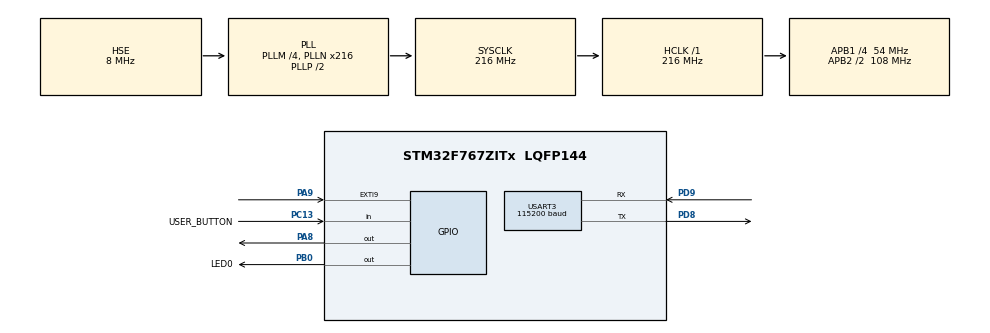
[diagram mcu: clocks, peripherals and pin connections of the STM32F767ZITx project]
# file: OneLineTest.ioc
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Mcu.Family=STM32F7
NVIC.USART3_IRQn=true\:2\:0\:true\:false\:true\:true\:true
RCC.PLLSourceVirtual=RCC_PLLSOURCE_HSE
RCC.CortexFreq_Value=216000000
PC13.Signal=GPIO_Input
PC14/OSC32_IN.Mode=LSE-External-Oscillator
PB0.GPIO_Label=LED0
PD9.Signal=USART3_RX
PC13.GPIO_Label=USER_BUTTON
RCC.APB1CLKDivider=RCC_HCLK_DIV4
PD9.Mode=Asynchronous
RCC.SYSCLKSource=RCC_SYSCLKSOURCE_PLLCLK
ProjectManager.StackSize=0x1000
USART3.VirtualMode-Asynchronous=VM_ASYNC
PA13.Signal=SYS_JTMS-SWDIO
USART3.BaudRate=115200
ProjectManager.TargetToolchain=MDK-ARM V5.27
PH0/OSC_IN.Mode=HSE-External-Clock-Source
RCC.HCLKFreq_Value=216000000
RCC.APB2TimFreq_Value=216000000
PA9.Signal=GPXTI9
PH1/OSC_OUT.Signal=RCC_OSC_OUT
PD8.Signal=USART3_TX
RCC.USBFreq_Value=216000000
TIM4.Prescaler=53
PD8.Mode=Asynchronous
RCC.AHBFreq_Value=216000000
RCC.HSE_VALUE=8000000
board=custom
RCC.VCOOutputFreq_Value=432000000
PH0/OSC_IN.Signal=RCC_OSC_IN
RCC.APB2Freq_Value=108000000
PA14.Mode=Serial_Wire
PA8.Signal=GPIO_Output
TIM4.Period=249
PA13.Mode=Serial_Wire
PH1/OSC_OUT.Mode=HSE-External-Clock-Source
Mcu.Name=STM32F767ZITx
RCC.SYSCLKFreq_VALUE=216000000
Mcu.Package=LQFP144
PC14/OSC32_IN.Signal=RCC_OSC32_IN
PC15/OSC32_OUT.Mode=LSE-External-Oscillator
NVIC.EXTI9_5_IRQn=true\:0\:0\:true\:false\:true\:true\:true
PA14.Signal=SYS_JTCK-SWCLK
ProjectManager.HeapSize=0x1000
RCC.HSI_VALUE=16000000
VP_TIM4_VS_ClockSourceINT.Mode=Internal
NVIC.PriorityGroup=NVIC_PRIORITYGROUP_4
RCC.APB2CLKDivider=RCC_HCLK_DIV2
RCC.PLLM=4
RCC.PLLN=216
PA9.GPIO_ModeDefaultEXTI=GPIO_MODE_IT_FALLING
RCC.APB1TimFreq_Value=108000000
PC15/OSC32_OUT.Signal=RCC_OSC32_OUT
NVIC.TIM4_IRQn=true\:1\:0\:true\:false\:true\:true\:true
RCC.APB1Freq_Value=54000000
PB0.Signal=GPIO_Output
PA8.GPIO_Speed=GPIO_SPEED_FREQ_VERY_HIGH

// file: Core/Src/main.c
/* USER CODE BEGIN Header */
/**
  ******************************************************************************
  * @file           : main.c
  * @brief          : Main program body
  ******************************************************************************
  * @attention
  *
  * <h2><center>&copy; Copyright (c) 2020 STMicroelectronics.
  * All rights reserved.</center></h2>
  *
  * This software component is licensed by ST under BSD 3-Clause license,
  * the "License"; You may not use this file except in compliance with the
  * License. You may obtain a copy of the License at:
  *                        opensource.org/licenses/BSD-3-Clause
  *
  ******************************************************************************
  */
/* USER CODE END Header */
#include "main.h"
#include "tim.h"
#include "usart.h"
#include "gpio.h"

/* USER CODE BEGIN Includes */

#include "bsp_one_line.h"

/* USER CODE END Includes */

void SystemClock_Config(void);

/* USER CODE BEGIN 0 */
uint32_t task_i = 0;
/* USER CODE END 0 */

int main(void)
{

  /* MCU Configuration--------------------------------------------------------*/

  /* Reset of all peripherals, Initializes the Flash interface and the Systick. */
  HAL_Init();

  /* Configure the system clock */
  SystemClock_Config();

  /* Initialize all configured peripherals */
  MX_GPIO_Init();
  MX_USART3_UART_Init();
  MX_TIM4_Init();
  /* USER CODE BEGIN 2 */

    __HAL_TIM_ENABLE_IT(&htim4, TIM_IT_UPDATE);
    HAL_TIM_Base_Start_IT(&htim4);

    my_printf("Hell World\r\n");

    uint8_t temp[10] = {0};

    HAL_Delay(1000);
  /* USER CODE END 2 */

  /* Infinite loop */
  /* USER CODE BEGIN WHILE */
  while (1)
  {
      task_i++;
      sprintf((char *)temp, "%04d\r\n", task_i);
      one_line_send(temp, 4);
      HAL_Delay(200);
    /* USER CODE END WHILE */

  }
}

void SystemClock_Config(void)
{
  RCC_OscInitTypeDef RCC_OscInitStruct = {0};
  RCC_ClkInitTypeDef RCC_ClkInitStruct = {0};
  RCC_PeriphCLKInitTypeDef PeriphClkInitStruct = {0};

  /** Configure LSE Drive Capability
  */
  HAL_PWR_EnableBkUpAccess();
  /** Configure the main internal regulator output voltage
  */
  __HAL_RCC_PWR_CLK_ENABLE();
  __HAL_PWR_VOLTAGESCALING_CONFIG(PWR_REGULATOR_VOLTAGE_SCALE1);
  /** Initializes the RCC Oscillators according to the specified parameters
  * in the RCC_OscInitTypeDef structure.
  */
  RCC_OscInitStruct.OscillatorType = RCC_OSCILLATORTYPE_HSE;
  RCC_OscInitStruct.HSEState = RCC_HSE_BYPASS;
  RCC_OscInitStruct.PLL.PLLState = RCC_PLL_ON;
  RCC_OscInitStruct.PLL.PLLSource = RCC_PLLSOURCE_HSE;
  RCC_OscInitStruct.PLL.PLLM = 4;
  RCC_OscInitStruct.PLL.PLLN = 216;
  RCC_OscInitStruct.PLL.PLLP = RCC_PLLP_DIV2;
  RCC_OscInitStruct.PLL.PLLQ = 2;
  if (HAL_RCC_OscConfig(&RCC_OscInitStruct) != HAL_OK)
  {
    Error_Handler();
  }
  /** Activate the Over-Drive mode
  */
  if (HAL_PWREx_EnableOverDrive() != HAL_OK)
  {
    Error_Handler();
  }
  /** Initializes the CPU, AHB and APB buses clocks
  */
  RCC_ClkInitStruct.ClockType = RCC_CLOCKTYPE_HCLK|RCC_CLOCKTYPE_SYSCLK
                              |RCC_CLOCKTYPE_PCLK1|RCC_CLOCKTYPE_PCLK2;
  RCC_ClkInitStruct.SYSCLKSource = RCC_SYSCLKSOURCE_PLLCLK;
  RCC_ClkInitStruct.AHBCLKDivider = RCC_SYSCLK_DIV1;
  RCC_ClkInitStruct.APB1CLKDivider = RCC_HCLK_DIV4;
  RCC_ClkInitStruct.APB2CLKDivider = RCC_HCLK_DIV2;

  if (HAL_RCC_ClockConfig(&RCC_ClkInitStruct, FLASH_LATENCY_7) != HAL_OK)
  {
    Error_Handler();
  }
  PeriphClkInitStruct.PeriphClockSelection = RCC_PERIPHCLK_USART3;
  PeriphClkInitStruct.Usart3ClockSelection = RCC_USART3CLKSOURCE_PCLK1;
  if (HAL_RCCEx_PeriphCLKConfig(&PeriphClkInitStruct) != HAL_OK)
  {
    Error_Handler();
  }
}

void Error_Handler(void)
{
}

/************************ (C) COPYRIGHT STMicroelectronics *****END OF FILE****/
